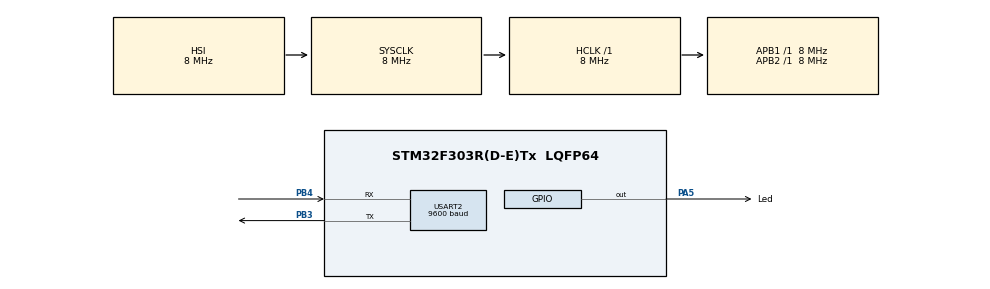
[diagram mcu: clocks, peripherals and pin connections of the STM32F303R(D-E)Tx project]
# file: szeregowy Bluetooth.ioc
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Mcu.Family=STM32F3
Mcu.Name=STM32F303R(D-E)Tx
Mcu.Package=LQFP64
NVIC.PriorityGroup=NVIC_PRIORITYGROUP_4
NVIC.USART2_IRQn=true\:0\:0\:false\:false\:true\:true\:true\:true
PA5.GPIO_Label=Led
PA5.Signal=GPIO_Output
PB3.Mode=Asynchronous
PB3.Signal=USART2_TX
PB4.Mode=Asynchronous
PB4.Signal=USART2_RX
ProjectManager.HeapSize=0x200
ProjectManager.StackSize=0x400
ProjectManager.TargetToolchain=STM32CubeIDE
RCC.AHBFreq_Value=8000000
RCC.APB1Freq_Value=8000000
RCC.APB2Freq_Value=8000000
RCC.CortexFreq_Value=8000000
RCC.HSE_VALUE=8000000
RCC.HSI_VALUE=8000000
RCC.LSE_VALUE=32768
RCC.SYSCLKFreq_VALUE=8000000
RCC.USBFreq_Value=16000000
USART2.BaudRate=9600
USART2.VirtualMode-Asynchronous=VM_ASYNC
board=custom

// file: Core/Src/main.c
/* USER CODE BEGIN Header */
/**
  ******************************************************************************
  * @file           : main.c
  * @brief          : Main program body
  ******************************************************************************
  * @attention
  *
  * Copyright (c) 2025 STMicroelectronics.
  * All rights reserved.
  *
  * This software is licensed under terms that can be found in the LICENSE file
  * in the root directory of this software component.
  * If no LICENSE file comes with this software, it is provided AS-IS.
  *
  ******************************************************************************
  */
/* USER CODE END Header */
#include "main.h"

/* USER CODE BEGIN Includes */
#include <string.h>
#include <stdio.h>
/* USER CODE END Includes */

UART_HandleTypeDef huart2;

/* USER CODE BEGIN PV */
uint8_t rx_byte;              // 1 bajt danych
char command_buffer[100];          // bufor na odebraną komendę
uint8_t cmd_index = 0;         // indeks do bufora

uint8_t run_mode=0;

/* USER CODE END PV */

void SystemClock_Config(void);
static void MX_GPIO_Init(void);
static void MX_USART2_UART_Init(void);
/* USER CODE BEGIN PFP */
void send_distance(){
	char wyswietl[40];
	for(int i=0; i<40; i++){
		wyswietl[i]=0;
	}
	uint16_t input_capture = 3000;
	sprintf(wyswietl,"distance=%d\n\r", input_capture/58);
	HAL_UART_Transmit(&huart2, (uint8_t* )wyswietl, strlen(wyswietl), HAL_MAX_DELAY);
}

void process_command(const char* cmd) {

}
void HAL_UART_RxCpltCallback(UART_HandleTypeDef *huart)
{
	if (huart->Instance == USART2)
	    {
	        if (rx_byte != '\n' && cmd_index < sizeof(command_buffer) - 1)
	        {
	        	command_buffer[cmd_index++] = rx_byte;
	        }
	        else
	        {
	        	command_buffer[cmd_index] = '\0';
	            cmd_index = 0;

	        }

        HAL_UART_Receive_IT(&huart2, &rx_byte, 1);
    }
}
/* USER CODE END PFP */

int main(void)
{

  /* MCU Configuration--------------------------------------------------------*/

  /* Reset of all peripherals, Initializes the Flash interface and the Systick. */
  HAL_Init();

  /* Configure the system clock */
  SystemClock_Config();

  /* Initialize all configured peripherals */
  MX_GPIO_Init();
  MX_USART2_UART_Init();

  /* Infinite loop */
  /* USER CODE BEGIN WHILE */
  HAL_UART_Receive_IT(&huart2, &rx_byte, 1);  // start odbioru

  while (1)
  {

	  if (strcmp(command_buffer, "start") == 0) {
		  run_mode = 1;
		  HAL_GPIO_WritePin(Led_GPIO_Port, Led_Pin, 1);
	  } else if (strcmp(command_buffer, "stop") == 0) {
		  run_mode = 0;
		  HAL_GPIO_WritePin(Led_GPIO_Port, Led_Pin, 0);
	  } else if (strcmp(command_buffer, "odleglosc") == 0) {
		  send_distance();
	  } else if (strcmp(command_buffer, "linia") == 0) {
		  //mode = LINE_FOLLOWING;
	  } else if (strcmp(command_buffer, "prawo") == 0) {
		  //drive_right();
	  } else if (strcmp(command_buffer, "lewo") == 0) {
		  //drive_left();
	  } else if (strcmp(command_buffer, "tyl") == 0) {
		  //drive_backward();
	  } else if (strcmp(command_buffer, "przod") == 0) {
		  //drive_forward();
	  } else if (strcmp(command_buffer, "obrot") == 0) {
		  //rotate_360();
	  }
    /* USER CODE END WHILE */

  }
}

void SystemClock_Config(void)
{
  RCC_OscInitTypeDef RCC_OscInitStruct = {0};
  RCC_ClkInitTypeDef RCC_ClkInitStruct = {0};
  RCC_PeriphCLKInitTypeDef PeriphClkInit = {0};

  /** Initializes the RCC Oscillators according to the specified parameters
  * in the RCC_OscInitTypeDef structure.
  */
  RCC_OscInitStruct.OscillatorType = RCC_OSCILLATORTYPE_HSI;
  RCC_OscInitStruct.HSIState = RCC_HSI_ON;
  RCC_OscInitStruct.HSICalibrationValue = RCC_HSICALIBRATION_DEFAULT;
  RCC_OscInitStruct.PLL.PLLState = RCC_PLL_NONE;
  if (HAL_RCC_OscConfig(&RCC_OscInitStruct) != HAL_OK)
  {
    Error_Handler();
  }

  /** Initializes the CPU, AHB and APB buses clocks
  */
  RCC_ClkInitStruct.ClockType = RCC_CLOCKTYPE_HCLK|RCC_CLOCKTYPE_SYSCLK
                              |RCC_CLOCKTYPE_PCLK1|RCC_CLOCKTYPE_PCLK2;
  RCC_ClkInitStruct.SYSCLKSource = RCC_SYSCLKSOURCE_HSI;
  RCC_ClkInitStruct.AHBCLKDivider = RCC_SYSCLK_DIV1;
  RCC_ClkInitStruct.APB1CLKDivider = RCC_HCLK_DIV1;
  RCC_ClkInitStruct.APB2CLKDivider = RCC_HCLK_DIV1;

  if (HAL_RCC_ClockConfig(&RCC_ClkInitStruct, FLASH_LATENCY_0) != HAL_OK)
  {
    Error_Handler();
  }
  PeriphClkInit.PeriphClockSelection = RCC_PERIPHCLK_USART2;
  PeriphClkInit.Usart2ClockSelection = RCC_USART2CLKSOURCE_PCLK1;
  if (HAL_RCCEx_PeriphCLKConfig(&PeriphClkInit) != HAL_OK)
  {
    Error_Handler();
  }
}

static void MX_USART2_UART_Init(void)
{

  huart2.Instance = USART2;
  huart2.Init.BaudRate = 9600;
  huart2.Init.WordLength = UART_WORDLENGTH_8B;
  huart2.Init.StopBits = UART_STOPBITS_1;
  huart2.Init.Parity = UART_PARITY_NONE;
  huart2.Init.Mode = UART_MODE_TX_RX;
  huart2.Init.HwFlowCtl = UART_HWCONTROL_NONE;
  huart2.Init.OverSampling = UART_OVERSAMPLING_16;
  huart2.Init.OneBitSampling = UART_ONE_BIT_SAMPLE_DISABLE;
  huart2.AdvancedInit.AdvFeatureInit = UART_ADVFEATURE_NO_INIT;
  if (HAL_UART_Init(&huart2) != HAL_OK)
  {
    Error_Handler();
  }

}

static void MX_GPIO_Init(void)
{
  GPIO_InitTypeDef GPIO_InitStruct = {0};

  /* GPIO Ports Clock Enable */
  __HAL_RCC_GPIOA_CLK_ENABLE();
  __HAL_RCC_GPIOB_CLK_ENABLE();

  /*Configure GPIO pin Output Level */
  HAL_GPIO_WritePin(Led_GPIO_Port, Led_Pin, GPIO_PIN_RESET);

  /*Configure GPIO pin : Led_Pin */
  GPIO_InitStruct.Pin = Led_Pin;
  GPIO_InitStruct.Mode = GPIO_MODE_OUTPUT_PP;
  GPIO_InitStruct.Pull = GPIO_NOPULL;
  GPIO_InitStruct.Speed = GPIO_SPEED_FREQ_LOW;
  HAL_GPIO_Init(Led_GPIO_Port, &GPIO_InitStruct);

}

void Error_Handler(void)
{
  __disable_irq();
  while (1)
  {
  }
}
